# DSS_DSS_COMMON_30200000h register map
Vendor: Texas Instruments
Peripheral module from a debugger description file (folder am62L).
Registers are 32-bit, read-write, reset 0x0 unless marked. A register's access mark holds for its fields unless they carry their own. Offsets are as the file gives them; lines under a group give offsets from that group; [hi:lo] are bit positions; {n}, {i} and the like mark numbered series; 'fields as' and 'values as' point back to an identical list; <NAME> marks a mode.

## DSS_COMMON
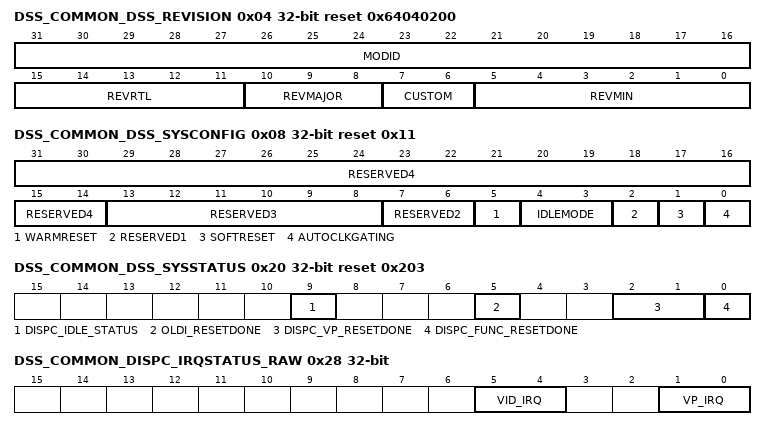
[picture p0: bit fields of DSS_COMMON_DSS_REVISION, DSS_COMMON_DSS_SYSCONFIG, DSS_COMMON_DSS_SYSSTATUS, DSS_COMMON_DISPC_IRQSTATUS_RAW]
0x04 DSS_COMMON_DSS_REVISION ro reset 0x64040200 — This register contains the K3_DSS revision number
  [31:16] MODID — Module ID Field
  [15:11] REVRTL — RTL Revision
  [10:8] REVMAJOR — Major Revision
  [7:6] CUSTOM
  [5:0] REVMIN — Minor Revision
0x08 DSS_COMMON_DSS_SYSCONFIG access per field reset 0x11 — This register controls various parameters related to software reset and IP idle
  [31:14] RESERVED4 ro — Write 0's for future compatibility. Read returns 0
  [13:8] RESERVED3 ro — Write 0's for future compatibility. Read returns 0
  [7:6] RESERVED2 ro — Write 0's for future compatibility. Read returns 0
  [5] WARMRESET rw — Warm reset. Setting this bit to 1 triggers a module warm reset. The bit is automatically reset by the hardware. During read, it always returns 0. The warm reset keeps the configuration registers unchanged
  [4:3] IDLEMODE rw — Deprecated
  [2] RESERVED1 ro — Write 0's for future compatibility. Read returns 0
  [1] SOFTRESET rw — Software reset. Setting this bit to 1 triggers a module reset. The bit is automatically reset by the hardware. During read, it always returns 0
  [0] AUTOCLKGATING rw — Internal clock gating strategy 0 Clocks are free-running1 Automatic clock gating strategy is applied, clocks are gated based on module activity
0x20 DSS_COMMON_DSS_SYSSTATUS ro reset 0x203 — This register provides status information about the module, excluding the interrupt status information
  [9] DISPC_IDLE_STATUS — Idle status of DISPC 0 DISPC is not in Idle1 DISPC is in Idle
  [5] OLDI_RESETDONE — Reset status of OLDI 0 Internal module reset is on-going1 Reset completed
  [2:1] DISPC_VP_RESETDONE — Bit[0]:Reset status of VP1 pixel clock domain; Bit[1]:should be written 0 0 Internal module reset is on-going1 Reset completed
  [0] DISPC_FUNC_RESETDONE — Reset status of DISPC Functional clock domain 0 Internal module reset is on-going1 Reset completed
0x24 DSS_COMMON_DISPC_IRQ_EOI wo — End-Of-Interrupt register, to be used if pulse interrupts are used
  [0] EOI — Write 1 to acknowledge a pulse IRQ 0 Write-0 : No action1 Write-1 : End-of-Interrupt
0x28 DSS_COMMON_DISPC_IRQSTATUS_RAW access not given — RAW Interrupt status. Raw status is set even if interrupt is not enabled. Write 1 to set the RAW status
  [5:4] VID_IRQ — Bit[4]: Reserved, Should be written with 0; Bit[5]:Register indicates the VIDL1 interrupt events; 0 Write-0 : No action, Read-0 : No event pending1 Write-1 : Set event, Read-1 : IRQ event pending (access R/W1TS)
  [1:0] VP_IRQ — Bit[0]: VP1 IRQ STATUS; Bit[1]: Reserved, Should be written with 0; 0 Write-0 : No action, Read-0 : No event pending1 Write-1 : Set event, Read-1 : IRQ event pending (access R/W1TS)
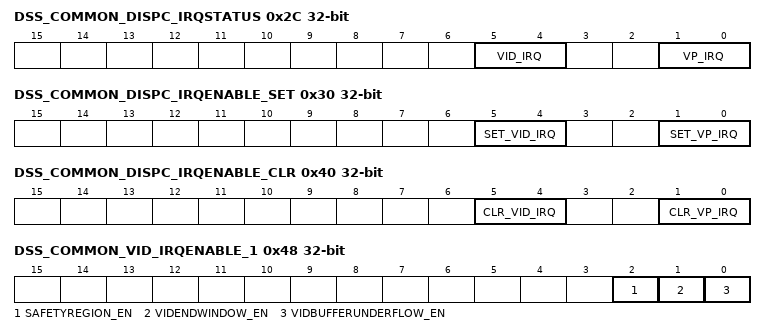
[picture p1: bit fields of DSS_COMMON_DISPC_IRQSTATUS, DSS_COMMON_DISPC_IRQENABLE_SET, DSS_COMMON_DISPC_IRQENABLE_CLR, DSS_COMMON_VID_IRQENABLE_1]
0x2C DSS_COMMON_DISPC_IRQSTATUS access not given — Interrupt status. Enabled status, isn't set unless event is enabled. Write 1 to clear the status after interrupt has been serviced. RAW status also gets cleared, i.e. even if not enabled
  [5:4] VID_IRQ — Bit[4]: Reserved, Should be written with 0; Bit[5]:VIDL1 IRQ STATUS; 0 Write-0 : No action, Read-0 : No event pending1 Write-1 : Clear pending event, if any, Read-1 : IRQ event pending (access R/W1TC)
  [1:0] VP_IRQ — Bit[0]: VP1 IRQ STATUS; Bit[1]: Reserved, Should be written with 0; 0 Write-0 : No action, Read-0 : No event pending1 Write-1 : Clear pending event, if any, Read-1 : IRQ event pending (access R/W1TC)
0x30 DSS_COMMON_DISPC_IRQENABLE_SET access not given — SET Interrupt enable. Write 1 to set interrupt enable. Readout equal to corresponding _CLR register
  [5:4] SET_VID_IRQ — Bit[4]: Reserved, Should be written with 0; Bit[5]:VIDL1 IRQ ; 0 Write-0 : No action, Read-0 : Interrupt Disabled1 Write-1 : Enable interrupt, Read-1 : Interrupt Enabled (access R/W1TS)
  [1:0] SET_VP_IRQ — Bit[0]: VP1 IRQ ; Bit[1]: Reserved, Should be written with 0; 0 Write-0 : No action, Read-0 : Interrupt Disabled1 Write-1 : Enable interrupt, Read-1 : Interrupt Enabled (access R/W1TS)
0x40 DSS_COMMON_DISPC_IRQENABLE_CLR access not given — CLR Interrupt enable. Write 1 to clear interrupt enable
  [5:4] CLR_VID_IRQ — Bit[4]: Reserved, Should be written with 0; Bit[5]:VIDL1 IRQ; 0 Write-0 : No action, Read-0 : Interrupt Disabled1 Write-1 : Clear interrupt, Read-1 : Interrupt Enabled (access R/W1TC)
  [1:0] CLR_VP_IRQ — Bit[0]: VP1 IRQ ; Bit[1]: Reserved, Should be written with 0; 0 Write-0 : No action, Read-0 : Interrupt Disabled1 Write-1 : Clear interrupt, Read-1 : Interrupt Enabled (access R/W1TC)
0x48 DSS_COMMON_VID_IRQENABLE_1 — This register allows to mask/unmask the VIDL1 internal sources of interrupt, on an event-by-event basis
  [2] SAFETYREGION_EN — Safety Feature IRQ. This is raised when FrameFreeze is detected or data mismatch occurs within the safety region 0 Event is masked1 Event generates an interrupt when it occurs
  [1] VIDENDWINDOW_EN — Video End Window. This is raised by the DMA engine when the full video data has been sent to the pipeline 0 Event is masked1 Event generates an interrupt when it occurs
  [0] VIDBUFFERUNDERFLOW_EN — Video DMA Buffer Underflow. This is raised when the DMA buffer does not have the data requested by the Video pipeline 0 Event is masked1 Event generates an interrupt when it occurs
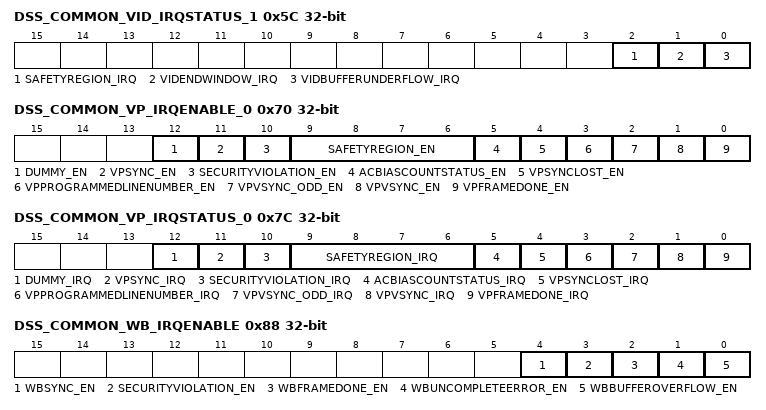
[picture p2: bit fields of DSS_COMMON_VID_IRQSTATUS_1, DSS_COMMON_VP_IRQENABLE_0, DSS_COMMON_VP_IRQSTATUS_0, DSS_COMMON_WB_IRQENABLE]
0x5C DSS_COMMON_VID_IRQSTATUS_1 access not given — This register groups all the status of the VIDL1 internal events that generate an interrupt. Write 1 to a clear a bit field
  [2] SAFETYREGION_IRQ — Safety Feature IRQ. This is raised when FrameFreeze is detected or data mismatch occurs within the safety region 0 Write: Status is unchanged, Read: Event is not pending1 Write: Status is reset, Read: Event is Pending (access R/W1TC)
  [1] VIDENDWINDOW_IRQ — Video End Window. This is raised by the DMA engine when the full video data has been sent to the pipeline 0 Write: Status is unchanged, Read: Event is not pending1 Write: Status is reset, Read: Event is Pending (access R/W1TC)
  [0] VIDBUFFERUNDERFLOW_IRQ — Video DMA Buffer Underflow. This is raised when the DMA buffer does not have the data requested by the Video pipeline 0 Write: Status is unchanged, Read: Event is not pending1 Write: Status is reset, Read: Event is Pending (access R/W1TC)
0x70 DSS_COMMON_VP_IRQENABLE_0 — This register allows to mask/unmask the VP_1 internal sources of interrupt, on an event-by-event basis
  [12] DUMMY_EN — Dummy IRQ for future use, In DSS_nano it should always be masked 0 Event is masked1 Event generates an interrupt when it occurs
  [11] VPSYNC_EN — Go bit clear event 0 Event is masked1 Event generates an interrupt when it occurs
  [10] SECURITYVIOLATION_EN — Security Violation interrupt for OVR/VP1. Non-secure OVR/VP1 connected to secure VID 0 Event is masked1 Event generates an interrupt when it occurs
  [9:6] SAFETYREGION_EN — Safety Feature IRQ. This is raised when FrameFreeze is detected or data mismatch occurs within the safety region 0 Event is masked1 Event generates an interrupt when it occurs
  [5] ACBIASCOUNTSTATUS_EN — AC BIAS transition counter has decremented to zero 0 Event is masked1 Event generates an interrupt when it occurs
  [4] VPSYNCLOST_EN — Synchronization Lost for Video Port 0 Event is masked1 Event generates an interrupt when it occurs
  [3] VPPROGRAMMEDLINENUMBER_EN — Programmed Line Number. It indicates that the scan of the display has reached the programmed user line number 0 Event is masked1 Event generates an interrupt when it occurs
  [2] VPVSYNC_ODD_EN — VSYNC for odd field from interlace mode only 0 Event is masked1 Event generates an interrupt when it occurs
  [1] VPVSYNC_EN — Vertical Synchronization for VP1 0 Event is masked1 Event generates an interrupt when it occurs
  [0] VPFRAMEDONE_EN — Frame Done for Video Port. VP1 output has been disabled by user. All the data have been sent 0 Event is masked1 Event generates an interrupt when it occurs
0x7C DSS_COMMON_VP_IRQSTATUS_0 access not given — This register groups all the status of the VP_1 internal events that generate an interrupt. Write 1 to a given bit resets this bit
  [12] DUMMY_IRQ — Dummy IRQ for future use 0 Write: Status is unchanged, Read: Event is not pending1 Write: Status is reset, Read: Event is Pending (access R/W1TC)
  [11] VPSYNC_IRQ — Go bit clear event 0 Write: Status is unchanged, Read: Event is not pending1 Write: Status is reset, Read: Event is Pending (access R/W1TC)
  [10] SECURITYVIOLATION_IRQ — Security Violation IRQ. Non-secure OVR/VP1 connected to secure VID 0 Write: Status is unchanged, Read: Event is not pending1 Write: Status is reset, Read: Event is Pending (access R/W1TC)
  [9:6] SAFETYREGION_IRQ — Safety Feature IRQ. This is raised when FrameFreeze is detected or data mismatch occurs within the safety region 0 Write: Status is unchanged, Read: Event is not pending1 Write: Status is reset, Read: Event is Pending (access R/W1TC)
  [5] ACBIASCOUNTSTATUS_IRQ — AC BIAS transition counter has decremented to zero 0 Write: Status is unchanged, Read: Event is not pending1 Write: Status is reset, Read: Event is Pending (access R/W1TC)
  [4] VPSYNCLOST_IRQ — Synchronization Lost on VP1 output. The required data are not output at the correct time due to too short blanking periods or stall of at least one pipelines associated with VP1 output 0 Write: Status is unchanged, Read: Event is not pending1 Write: Status is reset, Read: Event is Pending (access R/W1TC)
  [3] VPPROGRAMMEDLINENUMBER_IRQ — Programmed Line Number. It indicates that the scan of the display has reached the programmed user line number 0 Write: Status is unchanged, Read: Event is not pending1 Write: Status is reset, Read: Event is Pending (access R/W1TC)
  [2] VPVSYNC_ODD_IRQ — VSYNC for odd field. For interlace mode only 0 Write: Status is unchanged, Read: Event is not pending1 Write: Status is reset, Read: Event is Pending (access R/W1TC)
  [1] VPVSYNC_IRQ — Vertical Synchronization for VP1 output. It is used as VSYNC_EVEN in case of interlace mode 0 Write: Status is unchanged, Read: Event is not pending1 Write: Status is reset, Read: Event is Pending (access R/W1TC)
  [0] VPFRAMEDONE_IRQ — Frame Done for VP1. VP1 output has been disabled by user All the data have been sent 0 Write: Status is unchanged, Read: Event is not pending1 Write: Status is reset, Read: Event is Pending (access R/W1TC)
0x88 DSS_COMMON_WB_IRQENABLE — This register allows to mask/unmask the WB internal sources of interrupt, if WB pipeline is present, on an event-by-event basis
  [4] WBSYNC_EN — Write-back sync IRQ. Configuration copied from shadow to work for WB for next frame 0 Event is masked1 Event generates an interrupt when it occurs
  [3] SECURITYVIOLATION_EN — Security Violation IRQ. Non-secure WB connected to a secure VID/OVR 0 Event is masked1 Event generates an interrupt when it occurs
  [2] WBFRAMEDONE_EN — Write-back Frame Done 0 Event is masked1 Event generates an interrupt when it occurs
  [1] WBUNCOMPLETEERROR_EN — The write back buffer has been flushed before been fully drained. Can only occur in WB Capture Mode use-case 0 Event is masked1 Event generates an interrupt when it occurs
  [0] WBBUFFEROVERFLOW_EN — Write-back DMA Buffer Overflow. Can only occur in WB Capture Mode use-case 0 Event is masked1 Event generates an interrupt when it occurs
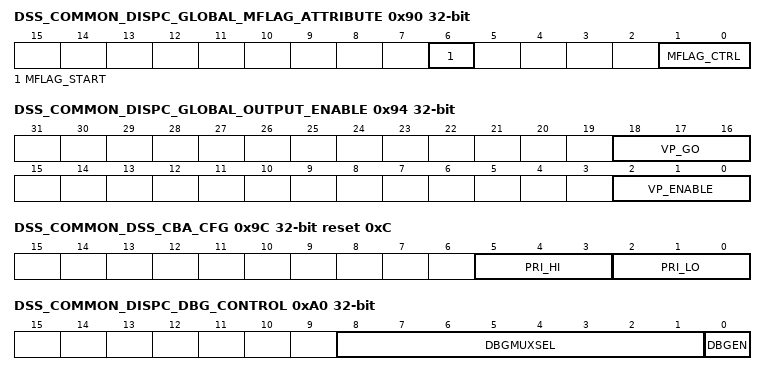
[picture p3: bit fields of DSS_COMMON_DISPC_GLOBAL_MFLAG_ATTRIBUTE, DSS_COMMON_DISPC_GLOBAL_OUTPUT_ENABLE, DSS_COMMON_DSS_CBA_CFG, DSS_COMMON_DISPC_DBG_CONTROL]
0x90 DSS_COMMON_DISPC_GLOBAL_MFLAG_ATTRIBUTE — MFLAG control register
  [6] MFLAG_START — MFLAG_START for DMA master port 0 When the DMA buffer is empty at the beginning of the frame, the MFLAG of each pipe is kept at 0 until PRELOAD is reached, then based on MFLAG_CTRL, MFLAG is generated and internal logic is arbitrating between pipeline requests1 Even at the beginning of the frame when the DMA buffer is empty, MFLAG_CTRL is used to determine how MFLAG dedicated to each pipe signal shall be driven
  [1:0] MFLAG_CTRL — MFLAG_CTRL for DMA master port 0 MFLAG mechanism is disabled: MFLAG out band signal is set to 01 MFLAG mechanism is enabled: MFLAG out band signal is always set to 12 MFLAG mechanism is enabled and MFLAG out band signal is dynamically set to 0 or 1 depending on the MFLAG rules
0x94 DSS_COMMON_DISPC_GLOBAL_OUTPUT_ENABLE — DISPC global output enable register. The ENABLE or GO bit for a particular output port is set when either the corresponding bit in this register is set or the corresponding bit within the sub-module is set. This register allows enabling multiple outputs synchronously [simultaneously], which is not possible if the ENABLE/GO bits are present only within the sub-module
  [18:16] VP_GO — Bit[16]: Global GO Command for the VP1 output. It is used to synchronize the pipelines associated with the VP1 output. wr: immediate; Bit[18:17]: Reserved, Should be written with 0; 0 The hardware has finished updating the internal shadow registers of the pipeline(s) connected to the VP1 output using the user values. The hardware resets the bit when the update is completed1 The user has finished to program the shadow registers of the pipeline(s) associated with the VP1 output and the hardware can update the internal registers at the VFP start period
  [2:0] VP_ENABLE — Bit[0]: Global VP1 Enable; Bit[2:1]: Reserved, Should be written with 0; 0 VP1 port is disabled1 VP1 port is enabled
0x9C DSS_COMMON_DSS_CBA_CFG reset 0xC — This register contains CBA specific config bits in DSS
  [5:3] PRI_HI — The value sent out on the PRI_HI bus from DSS to CBA Indicates the priority level for high-priority [MFLAG] transactions. Value of 0x0 indicates highest priority Value of 0x7 indicates lowest priority
  [2:0] PRI_LO — The value sent out on the PRI_LO bus from DSS to CBA Indicates the priority level for normal [non-MFLAG] transactions. Value of 0x0 indicates highest priority Value of 0x7 indicates lowest priority
0xA0 DSS_COMMON_DISPC_DBG_CONTROL — DISPC debug status control register
  [8:1] DBGMUXSEL — Mux select for the debug status 0 8 values to select any 4bytes, order from LSB 4bytes to MSB 4bytes, at a time from the 32byte VID1 debug bus8 8 values to select any 4bytes, order from LSB 4bytes to MSB 4bytes, at a time from the 32byte VID1 debug bus17 Select OVR1 debug bus, 4bytes18 Select OVR2 debug bus, 4bytes19 Select VP1 debug bus , 8bytes21 Select VP2 debug bus , 8bytes23 Select MISC debug bus, 4bytes
  [0] DBGEN — Enable debug ports 0 DBGDIS1 DBGEN
0xA4 DSS_COMMON_DISPC_DBG_STATUS ro — DISPC debug status register
  [31:0] DBGOUT — Debug status
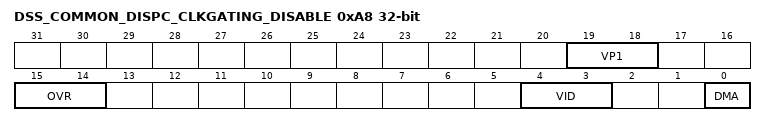
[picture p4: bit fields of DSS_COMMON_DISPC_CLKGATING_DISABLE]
0xA8 DSS_COMMON_DISPC_CLKGATING_DISABLE — Register to control clock gating at DISPC sub-module level
  [19:18] VP1 — Bit[18]: Clock gating control for VP1; Bit[19]: Reserved, should be written 0; 0 Clock-Gating is enabled1 Clock-gating is disabled. Clocks are free running
  [15:14] OVR — Bit[14]: Clock gating control for OVR; Bit[15]:Reserved, should be written 0 0 Clock-Gating is enabled1 Clock-gating is disabled. Clocks are free running
  [4:3] VID — Bit[3]: Reserved , should be written 0; Bit[4] :Clock gating control for VIDL1 0 Clock-Gating is enabled1 Clock-gating is disabled. Clocks are free running
  [0] DMA — Clock gating control for DMA 0 Clock-Gating is enabled1 Clock-gating is disabled. Clocks are free running
0xAC DSS_COMMON_DISPC_SECURE_DISABLE — Disable security settings throughout DSS IP. COMMON_1.DISPC_SECURE bits are honoured only if COMMON.DISPC_SECURE_DISABLE =0
  [0] SECURE_DISABLE — Secure disable bit 0 Secure bits, in COMMON_1.DISPC_SECURE, are active1 Secure bits, in COMMON_1.DISPC_SECURE, are not active and IP will behave as non-secure
